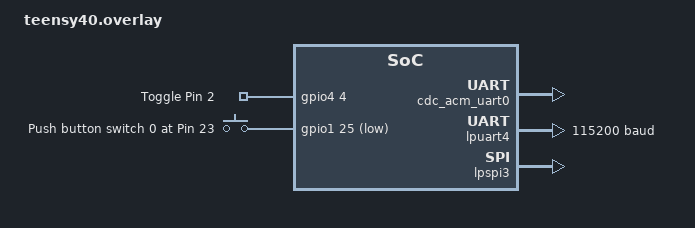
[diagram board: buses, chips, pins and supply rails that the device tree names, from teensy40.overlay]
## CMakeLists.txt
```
# Find Zephyr. This also loads Zephyr's build system.
cmake_minimum_required(VERSION 3.13.1)
# find_package(Zephyr)
find_package(Zephyr REQUIRED HINTS $ENV{ZEPHYR_BASE})
project(my_zephyr_app)

# Add your source file to the "app" target. This must come after
# find_package(Zephyr) which defines the target.
target_sources(app PRIVATE src/main.c)
target_sources(app PRIVATE src/led.c)
target_sources(app PRIVATE src/pin.c)
target_sources(app PRIVATE src/button.c)
target_sources(app PRIVATE src/uart.c)
target_sources(app PRIVATE src/spi.c)
target_sources(app PRIVATE src/sdhc.c)
target_sources(app PRIVATE src/dhcp.c)

include_directories(${CMAKE_CURRENT_SOURCE_DIR}/src)

zephyr_code_relocate(src/*.c DTCM_DATA)
zephyr_code_relocate(src/*.c ITCM_TEXT)
```

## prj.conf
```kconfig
# GENERAL
CONFIG_CODE_DATA_RELOCATION=y
CONFIG_LOG=y
CONFIG_GPIO=y

# SDHC
CONFIG_FILE_SYSTEM=y
CONFIG_FAT_FILESYSTEM_ELM=y

# USB (incl. console output)
CONFIG_USB_DEVICE_STACK=y
CONFIG_USB_UART_CONSOLE=y
CONFIG_USB_DEVICE_PRODUCT="Zephyr first steps"
CONFIG_USB_DRIVER_LOG_LEVEL_ERR=y

# ETH
CONFIG_NETWORKING=y
CONFIG_NET_IPV6=n
CONFIG_NET_IPV4=y
CONFIG_NET_DHCPV4=y

CONFIG_NET_MGMT=y
CONFIG_NET_MGMT_EVENT=y

# SPI
CONFIG_SPI=y
```

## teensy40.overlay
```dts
/*
 * Copyright (c) 2020, Bernhard Kraemer
 *
 * SPDX-License-Identifier: Apache-2.0
 */


/ {
    aliases {
      toggle = &toggle_gpio;
      sw0 = &button0;
    };

    chosen {
      zephyr,console = &cdc_acm_uart0;
    };
        
    app-gpios {
      compatible = "gpio-keys";
      toggle_gpio: toggle-gpio {
        gpios = <&gpio4 4 GPIO_ACTIVE_HIGH>;
        label = "Toggle Pin 2";
      };
      button0: button_0 {
        gpios = < &gpio1 25 GPIO_ACTIVE_LOW >;
        label = "Push button switch 0 at Pin 23";
      };
    };
};

&zephyr_udc0 {
  cdc_acm_uart0: cdc_acm_uart0 {
    compatible = "zephyr,cdc-acm-uart";
    label = "CDC_ACM_0";
  };
};

&lpuart6 {
  status = "disabled";
};

&lpuart4 {
  status = "okay";
  current-speed = < 115200 >;
};

&lpspi3 {
  status = "okay";
};
```

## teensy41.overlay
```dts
/*
 * Copyright (c) 2020, Bernhard Kraemer
 *
 * SPDX-License-Identifier: Apache-2.0
 */


/ {
    aliases {
      toggle = &toggle_gpio;
      sw0 = &button0;
    };

    chosen {
      zephyr,console = &cdc_acm_uart0;
    };

    app-gpios {
      compatible = "gpio-keys";
      toggle_gpio: toggle-gpio {
        gpios = <&gpio1 21 GPIO_ACTIVE_HIGH>;
        label = "Toggle Pin 41";
      };
      button0: button_0 {
        gpios = < &gpio1 25 GPIO_ACTIVE_LOW >;
        label = "Push button switch 0 at Pin 23";
      };
    };
};

&zephyr_udc0 {
  cdc_acm_uart0: cdc_acm_uart0 {
    compatible = "zephyr,cdc-acm-uart";
    label = "CDC_ACM_0";
  };
};

&lpuart6 {
  status = "disabled";
};

&lpuart4 {
  status = "okay";
  current-speed = < 115200 >;
};
```

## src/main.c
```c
/**
 * @file main.c
 * @author Bernhard Kraemer
 * @brief Application startup
 * @version 0.1
 * @date 2020-11-15
 * 
 * @copyright Copyright (c) 2020
 * 
 */

/*** Imported Objects ***************************************************************/
#include <zephyr.h>
#include <logging/log.h>

#include <usb/usb_device.h>

/*** Constants **********************************************************************/
#define LOG_MODULE_NAME sys

#define START_DELAY 400

/*** Types **************************************************************************/

/*** Variables **********************************************************************/

/*** Function Prototypes ************************************************************/
void main(void);

/*** Macros *************************************************************************/
LOG_MODULE_REGISTER(LOG_MODULE_NAME, LOG_LEVEL_DBG);

BUILD_ASSERT(DT_NODE_HAS_COMPAT(DT_CHOSEN(zephyr_console), zephyr_cdc_acm_uart),
	     "Console device is not ACM CDC UART device");

/*** Function implementation ********************************************************/

void main(void)
{
	uint32_t version = sys_kernel_version_get();

	if (usb_enable(NULL)) {
		return;
	}

	/* Sleep some time after boot to give USB-Client a chance to connect 
	 * before first log output is produced. 
	 */
	k_msleep(START_DELAY);

	LOG_INF("Started zephyr %u.%u.%u on board %s/%s.", SYS_KERNEL_VER_MAJOR(version), SYS_KERNEL_VER_MINOR(version), SYS_KERNEL_VER_PATCHLEVEL(version), CONFIG_ARCH, CONFIG_BOARD);
}
```

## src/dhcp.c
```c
/**
 * @file socket.c
 * @author Bernhard Kraemer
 * @brief TCPV4 dhcp client.
 * @version 0.1
 * @date 2020-12-20
 * 
 * @copyright Copyright (c) 2020
 * 
 */

/*** Imported Objects ***************************************************************/
#include <zephyr.h>
#include <logging/log.h>
#include <globals.h>

#include <stdio.h>
#include <stdlib.h>
#include <errno.h>

#include <net/net_if.h>
#include <net/net_core.h>
#include <net/net_context.h>
#include <net/net_mgmt.h>

/*** Constants **********************************************************************/
#define LOG_MODULE_NAME dhcp

#define START_DELAY     500
#define STACK_SIZE      5000
#define PRIORITY        5

/*** Types **************************************************************************/

/*** Variables **********************************************************************/
static struct net_mgmt_event_callback mgmt_cb;

/*** Function Prototypes ************************************************************/
void socket_main_f();
static void handler(struct net_mgmt_event_callback *cb,
		    uint32_t mgmt_event,
		    struct net_if *iface);

/*** Macros *************************************************************************/
LOG_MODULE_REGISTER(LOG_MODULE_NAME, LOG_LEVEL_DBG);

K_THREAD_DEFINE(socket_id, STACK_SIZE, socket_main_f, NULL, NULL, NULL,
                PRIORITY, 0, START_DELAY);

/*** Function implementation ********************************************************/

 void socket_main_f(void)
{
	struct net_if *iface;

	LOG_INF("Thread started");

	net_mgmt_init_event_callback(&mgmt_cb, handler,
				     NET_EVENT_IPV4_ADDR_ADD);
	net_mgmt_add_event_callback(&mgmt_cb);
 
	iface = net_if_get_default();

	net_dhcpv4_start(iface);
}

static void handler(struct net_mgmt_event_callback *cb,
		    uint32_t mgmt_event,
		    struct net_if *iface)
{
	int i = 0;

	if (mgmt_event != NET_EVENT_IPV4_ADDR_ADD) {
		return;
	}

	for (i = 0; i < NET_IF_MAX_IPV4_ADDR; i++) {
		char buf[NET_IPV4_ADDR_LEN];

		if (iface->config.ip.ipv4->unicast[i].addr_type !=
							NET_ADDR_DHCP) {
			continue;
		}

		LOG_INF("Your address: %s",
			log_strdup(net_addr_ntop(AF_INET,
			    &iface->config.ip.ipv4->unicast[i].address.in_addr,
						  buf, sizeof(buf))));
		LOG_INF("Lease time: %u seconds",
			 iface->config.dhcpv4.lease_time);
		LOG_INF("Subnet: %s",
			log_strdup(net_addr_ntop(AF_INET,
				       &iface->config.ip.ipv4->netmask,
				       buf, sizeof(buf))));
		LOG_INF("Router: %s",
			log_strdup(net_addr_ntop(AF_INET,
						 &iface->config.ip.ipv4->gw,
						 buf, sizeof(buf))));
	}
}
```

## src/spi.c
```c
/**
 * @file spi.c
 * @author Bernhard Kraemer
 * @brief SPI sample, only tx.
 * @version 0.1
 * @date 2021-01-18
 * 
 * @copyright Copyright (c) 2021
 * 
 */

/*** Imported Objects ***************************************************************/
#include <zephyr.h>
#include <logging/log.h>

#include <drivers/spi.h>
#include <globals.h>

/*** Constants **********************************************************************/
#define LOG_MODULE_NAME spi

#define START_DELAY     500
#define STACK_SIZE      500
#define PRIORITY        -5

#define SPI_DEV         DT_LABEL(DT_NODELABEL(lpspi3))

/*** Types **************************************************************************/


/*** Variables **********************************************************************/


/*** Function Prototypes ************************************************************/
void spi_main_f();
static int spi_send(const struct device *spi,
			  const struct spi_config *spi_cfg,
			  const uint8_t *data, size_t len);
static int spi_send_str(const struct device *spi,
			      const struct spi_config *spi_cfg,
			      const unsigned char *str);

/*** Macros *************************************************************************/
LOG_MODULE_REGISTER(LOG_MODULE_NAME, LOG_LEVEL_DBG);

K_THREAD_DEFINE(spi_id, STACK_SIZE, spi_main_f, NULL, NULL, NULL,
                PRIORITY, 0, START_DELAY);

/*** Function implementation ********************************************************/

static int spi_send(const struct device *spi,
			  const struct spi_config *spi_cfg,
			  const uint8_t *data, size_t len)
{
	const struct spi_buf_set tx = {
		.buffers = &(const struct spi_buf){
			.buf = (uint8_t *)data,
			.len = len,
		},
		.count = 1,
	};

	return spi_write(spi, spi_cfg, &tx);
}

static int spi_send_str(const struct device *spi,
			      const struct spi_config *spi_cfg,
			      const unsigned char *str)
{
	return spi_send(spi, spi_cfg, str, strlen(str));
}

void spi_main_f()
{
    int ret;
    const struct device *spi;
    struct spi_config cfg;

    spi = device_get_binding(SPI_DEV);
    if (spi == NULL)
    {
        LOG_ERR("Device binding is NULL");
        return;
    }

    cfg.frequency = 10000U;
    cfg.operation = SPI_WORD_SET(8) | SPI_TRANSFER_MSB | SPI_OP_MODE_MASTER;
    cfg.cs = NULL;

    LOG_INF("Thread started");
    
    while (1)
    {
        ret = spi_send_str(spi, &cfg, "Lorem ipsum dolor sit amet");
        if (ret != 0)
        {
            LOG_ERR("Failed to write %s, Error: %u", SPI_DEV, ret);
            return;
        }

        k_sleep(K_MSEC(5000));
    }
}
```
